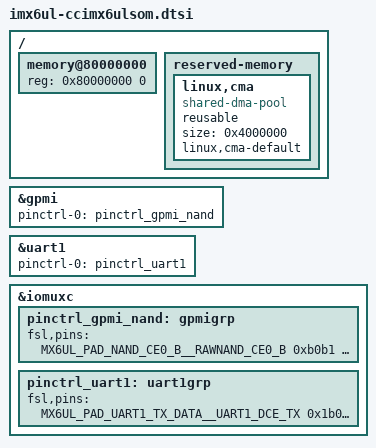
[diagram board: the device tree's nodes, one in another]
// SPDX-License-Identifier: GPL-2.0
/*
 * Digi International's ConnectCore 6UL System-On-Module device tree source
 *
 * Copyright 2018 Digi International, Inc.
 *
 */

/ {
	memory@80000000 {
		device_type = "memory";
		reg = <0x80000000 0>; /* will be filled by U-Boot */
	};

	reserved-memory {
		#address-cells = <1>;
		#size-cells = <1>;
		ranges;

		linux,cma {
			compatible = "shared-dma-pool";
			reusable;
			size = <0x4000000>;
			linux,cma-default;
		};
	};
};

&gpmi {
	pinctrl-names = "default";
	pinctrl-0 = <&pinctrl_gpmi_nand>;
	status = "okay";
};

&uart1 {
	pinctrl-names = "default";
	pinctrl-0 = <&pinctrl_uart1>;
	status = "okay";
};

&iomuxc {
	pinctrl_gpmi_nand: gpmigrp {
		fsl,pins = <
			MX6UL_PAD_NAND_CE0_B__RAWNAND_CE0_B	0xb0b1
			MX6UL_PAD_NAND_RE_B__RAWNAND_RE_B	0xb0b1
			MX6UL_PAD_NAND_WE_B__RAWNAND_WE_B	0xb0b1
			MX6UL_PAD_NAND_WP_B__RAWNAND_WP_B	0xb0b1
			MX6UL_PAD_NAND_ALE__RAWNAND_ALE		0xb0b1
			MX6UL_PAD_NAND_CLE__RAWNAND_CLE		0xb0b1
			MX6UL_PAD_NAND_DATA00__RAWNAND_DATA00	0xb0b1
			MX6UL_PAD_NAND_DATA01__RAWNAND_DATA01	0xb0b1
			MX6UL_PAD_NAND_DATA02__RAWNAND_DATA02	0xb0b1
			MX6UL_PAD_NAND_DATA03__RAWNAND_DATA03	0xb0b1
			MX6UL_PAD_NAND_DATA04__RAWNAND_DATA04	0xb0b1
			MX6UL_PAD_NAND_DATA05__RAWNAND_DATA05	0xb0b1
			MX6UL_PAD_NAND_DATA06__RAWNAND_DATA06	0xb0b1
			MX6UL_PAD_NAND_DATA07__RAWNAND_DATA07	0xb0b1
			MX6UL_PAD_NAND_READY_B__RAWNAND_READY_B	0xb0b1
		>;
	};

    pinctrl_uart1: uart1grp {
        fsl,pins = <
            MX6UL_PAD_UART1_TX_DATA__UART1_DCE_TX 0x1b0b1
            MX6UL_PAD_UART1_RX_DATA__UART1_DCE_RX 0x1b0b1
        >;
    };
};

